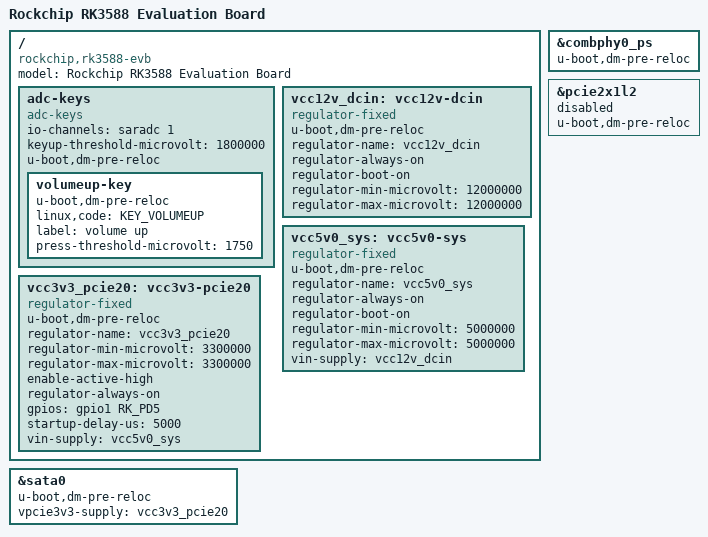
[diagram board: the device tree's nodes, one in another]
// SPDX-License-Identifier: (GPL-2.0+ OR MIT)
/*
 * Copyright (c) 2021 Rockchip Electronics Co., Ltd
 *
 */

/dts-v1/;
#include "rk3588.dtsi"
#include "rk3588-u-boot.dtsi"
#include <dt-bindings/input/input.h>

/ {
	model = "Rockchip RK3588 Evaluation Board";
	compatible = "rockchip,rk3588-evb", "rockchip,rk3588";

	adc-keys {
		compatible = "adc-keys";
		io-channels = <&saradc 1>;
		io-channel-names = "buttons";
		keyup-threshold-microvolt = <1800000>;
		u-boot,dm-pre-reloc;
		status = "okay";

		volumeup-key {
			u-boot,dm-pre-reloc;
			linux,code = <KEY_VOLUMEUP>;
			label = "volume up";
			press-threshold-microvolt = <1750>;
		};
	};

	vcc12v_dcin: vcc12v-dcin {
		u-boot,dm-pre-reloc;
		compatible = "regulator-fixed";
		regulator-name = "vcc12v_dcin";
		regulator-always-on;
		regulator-boot-on;
		regulator-min-microvolt = <12000000>;
		regulator-max-microvolt = <12000000>;
	};

	vcc5v0_sys: vcc5v0-sys {
		u-boot,dm-pre-reloc;
		compatible = "regulator-fixed";
		regulator-name = "vcc5v0_sys";
		regulator-always-on;
		regulator-boot-on;
		regulator-min-microvolt = <5000000>;
		regulator-max-microvolt = <5000000>;
		vin-supply = <&vcc12v_dcin>;
	};

	vcc3v3_pcie20: vcc3v3-pcie20 {
		u-boot,dm-pre-reloc;
		compatible = "regulator-fixed";
		regulator-name = "vcc3v3_pcie20";
		regulator-min-microvolt = <3300000>;
		regulator-max-microvolt = <3300000>;
		enable-active-high;
		regulator-always-on;
		gpios = <&gpio1 RK_PD5 GPIO_ACTIVE_HIGH>;
		startup-delay-us = <5000>;
		vin-supply = <&vcc5v0_sys>;
	};
};

&combphy0_ps {
	u-boot,dm-pre-reloc;
	status = "okay";
};

&sata0 {
	u-boot,dm-pre-reloc;
	status = "okay";
	vpcie3v3-supply = <&vcc3v3_pcie20>;
};

&pcie2x1l2 {
	u-boot,dm-pre-reloc;
	status = "disabled";
};
